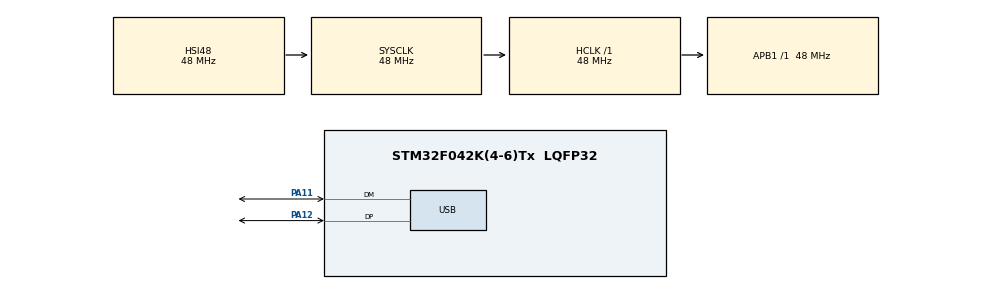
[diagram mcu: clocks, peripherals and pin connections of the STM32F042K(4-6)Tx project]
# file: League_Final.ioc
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Mcu.Family=STM32F0
Mcu.Name=STM32F042K(4-6)Tx
Mcu.Package=LQFP32
NVIC.USB_IRQn=true\:0\:0\:false\:false\:true\:false\:true
PA11.Mode=Device
PA11.Signal=USB_DM
PA12.Mode=Device
PA12.Signal=USB_DP
PA13.GPIO_Label=SWDIO
PA13.Mode=Serial_Wire
PA13.Signal=SYS_SWDIO
PA14.GPIO_Label=SWCLK
PA14.Mode=Serial_Wire
PA14.Signal=SYS_SWCLK
ProjectManager.HeapSize=0x100
ProjectManager.StackSize=0x400
ProjectManager.TargetToolchain=SW4STM32
RCC.AHBFreq_Value=48000000
RCC.APB1Freq_Value=48000000
RCC.APB1TimFreq_Value=48000000
RCC.HCLKFreq_Value=48000000
RCC.SYSCLKFreq_VALUE=48000000
RCC.SYSCLKSource=RCC_SYSCLKSOURCE_HSI48
USB_DEVICE.CLASS_NAME_FS=HID
USB_DEVICE.USBD_MAX_NUM_INTERFACES=2
USB_DEVICE.VirtualMode=Hid
USB_DEVICE.VirtualModeFS=Hid_FS
VP_USB_DEVICE_VS_USB_DEVICE_HID_FS.Mode=HID_FS
board=NUCLEO-F042K6

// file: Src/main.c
/* USER CODE BEGIN Header */
/**
  ******************************************************************************
  * @file           : main.c
  * @brief          : Main program body
  ******************************************************************************
  * @attention
  *
  * <h2><center>&copy; Copyright (c) 2020 STMicroelectronics.
  * All rights reserved.</center></h2>
  *
  * This software component is licensed by ST under Ultimate Liberty license
  * SLA0044, the "License"; You may not use this file except in compliance with
  * the License. You may obtain a copy of the License at:
  *                             www.st.com/SLA0044
  *
  ******************************************************************************
  */
/* USER CODE END Header */

#include "main.h"
#include "usb_device.h"
#include "usbd_hid.h"
#include "gpio_poller.h"
#include "joystick.h"

typedef struct Mouse_Report
{
	uint8_t report_id; //must be 2
	uint8_t buttons;
	int8_t x_pos;
	int8_t y_pos;
} Mouse_Report;

typedef struct Keyboard_Report
{
	uint8_t report_id; //must be 1
    uint8_t modifier; //unused
    uint8_t reserved; //unused
    uint8_t keycode[6];
} Keyboard_Report;

void SystemClock_Config(void);

/* USER CODE BEGIN 0 */

void send_keyboard_report()
{
	button_state* buttons = get_states();

	Keyboard_Report rep1 = {1, 0, 0, {0,0,0,0,0,0}};
	uint8_t fill_loc = 0;

	for(int i = 0; i < NUM_BUTTONS; i++)
	{
		//if keycode is null, then button is for non-keyboard use
		if(buttons[i].state && definitions[i].keycode)
		{
			rep1.keycode[fill_loc++] = definitions[i].keycode;
		}
	}
	USBD_HID_SendReport(&hUsbDeviceFS, (uint8_t*)&rep1, sizeof(rep1));
}

void send_mouse_report()
{
	button_state* buttons = get_states();

	Mouse_Report rep2 = {2, 0, 0, 0};

	//mouse buttons
	if(buttons[L_CLICK].state)
		rep2.buttons |= 1;

	if(buttons[R_CLICK].state || get_autoclick())
		rep2.buttons |= (1 << 1);

	//mouse cursor
	int8_t x,y;
	get_value(&x, &y);
	rep2.x_pos = x;
	rep2.y_pos = y;

	USBD_HID_SendReport(&hUsbDeviceFS, (uint8_t*)&rep2, sizeof(rep2));
}

/* USER CODE END 0 */

int main(void)
{

  /* MCU Configuration--------------------------------------------------------*/

  /* Reset of all peripherals, Initializes the Flash interface and the Systick. */
  HAL_Init();

  /* Configure the system clock */
  SystemClock_Config();

  /* Initialize all configured peripherals */
  MX_USB_DEVICE_Init();
  /* USER CODE BEGIN 2 */

  io_init();
  joystick_init();
  set_calibration_point();
  /* USER CODE END 2 */

  /* Infinite loop */
  /* USER CODE BEGIN WHILE */
  	int send_mouse = 0;
	while (1)
	{
		int counter = 0;
		while(counter < 20) //20 debounce samples = 5ms
		{
			while(!next_sample){}

			debounce_sample();
			counter++;
		}

		//switch between sending mouse and keyboard updates at polling frequency
		if(send_mouse)
			send_mouse_report();
		else
			send_keyboard_report();

		send_mouse = !send_mouse;
	}
  /* USER CODE END 3 */
}

void SystemClock_Config(void)
{
  RCC_OscInitTypeDef RCC_OscInitStruct = {0};
  RCC_ClkInitTypeDef RCC_ClkInitStruct = {0};
  RCC_PeriphCLKInitTypeDef PeriphClkInit = {0};

  /** Initializes the CPU, AHB and APB busses clocks
  */
  RCC_OscInitStruct.OscillatorType = RCC_OSCILLATORTYPE_HSI48;
  RCC_OscInitStruct.HSI48State = RCC_HSI48_ON;
  RCC_OscInitStruct.PLL.PLLState = RCC_PLL_NONE;
  if (HAL_RCC_OscConfig(&RCC_OscInitStruct) != HAL_OK)
  {
    Error_Handler();
  }
  /** Initializes the CPU, AHB and APB busses clocks
  */
  RCC_ClkInitStruct.ClockType = RCC_CLOCKTYPE_HCLK|RCC_CLOCKTYPE_SYSCLK
                              |RCC_CLOCKTYPE_PCLK1;
  RCC_ClkInitStruct.SYSCLKSource = RCC_SYSCLKSOURCE_HSI48;
  RCC_ClkInitStruct.AHBCLKDivider = RCC_SYSCLK_DIV1;
  RCC_ClkInitStruct.APB1CLKDivider = RCC_HCLK_DIV1;

  if (HAL_RCC_ClockConfig(&RCC_ClkInitStruct, FLASH_LATENCY_1) != HAL_OK)
  {
    Error_Handler();
  }
  PeriphClkInit.PeriphClockSelection = RCC_PERIPHCLK_USB;
  PeriphClkInit.UsbClockSelection = RCC_USBCLKSOURCE_HSI48;

  if (HAL_RCCEx_PeriphCLKConfig(&PeriphClkInit) != HAL_OK)
  {
    Error_Handler();
  }
}

void Error_Handler(void)
{
}

/************************ (C) COPYRIGHT STMicroelectronics *****END OF FILE****/
